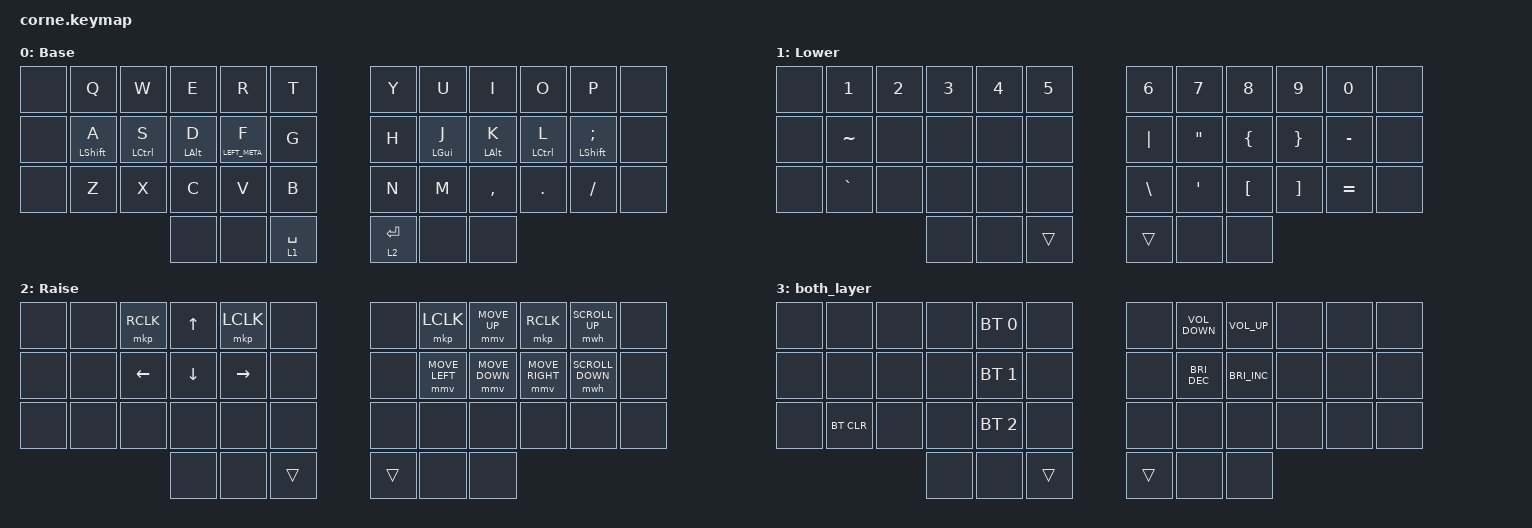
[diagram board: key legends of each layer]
/*
 * Copyright (c) 2020 The ZMK Contributors
 *
 * SPDX-License-Identifier: MIT
 * MOUSE SUPPORT: https://gist.github.com/krissen/dd27082e7ab0575619c7a31f4d2ec7ae
 * KEYMAP EDITOR: https://github.com/nickcoutsos/keymap-editor
 * MOUSE WHEEL REFERENCE: https://git.kemonine.info/kemonine/keyboard/commit/45d8c3530a40c2923cae3f1c22f27f6ed89b84cc

 * MOUSE CODES
 * &mkp RCLK   
 * &mkp LCLK
 * 
 * &mwh SCROLL_UP 		
 * &mwh SCROLL_DOWN 		
 * 
 * &mmv MOVE_UP  
 * &mmv MOVE_LEFT  
 * &mmv MOVE_DOWN  
 * &mmv MOVE_RIGHT

 */

#include <behaviors.dtsi>
#include <dt-bindings/zmk/bt.h>
#include <dt-bindings/zmk/keys.h>
#include <dt-bindings/zmk/mouse.h>

#define U_MOUSE_MOVE_MAX 1100                     /* <--- New max speed setting (default: 600) */

#undef MOVE_UP
#undef MOVE_DOWN
#undef MOVE_LEFT
#undef MOVE_RIGHT

#define MOVE_UP MOVE_VERT(-U_MOUSE_MOVE_MAX)
#define MOVE_DOWN MOVE_VERT(U_MOUSE_MOVE_MAX)
#define MOVE_LEFT MOVE_HOR(-U_MOUSE_MOVE_MAX)
#define MOVE_RIGHT MOVE_HOR(U_MOUSE_MOVE_MAX)

&mmv {
    time-to-max-speed-ms = <50>;/* <--- How long time until max speed is reached (default: 500) */
};

#define U_MOUSE_SCROLL_MAX 50                    /* <--- New max speed setting (default: 10) */

#undef SCROLL_UP
#undef SCROLL_DOWN
#undef SCROLL_LEFT
#undef SCROLL_RIGHT

#define SCROLL_UP SCROLL_VERT(U_MOUSE_SCROLL_MAX)
#define SCROLL_DOWN SCROLL_VERT(-U_MOUSE_SCROLL_MAX)
#define SCROLL_LEFT SCROLL_HOR(-U_MOUSE_SCROLL_MAX)
#define SCROLL_RIGHT SCROLL_HOR(U_MOUSE_SCROLL_MAX)

&mwh {
    time-to-max-speed-ms = <50>;/* <--- How long time until max speed is reached */
};

/ {
    combos {
        compatible = "zmk,combos";

        tab {
            bindings = <&kp TAB>;
            key-positions = <13 14>;
        };

        esc {
            bindings = <&kp ESC>;
            key-positions = <2 1>;
        };

        backspace {
            bindings = <&kp BACKSPACE>;
            key-positions = <9 10>;
        };

        keyT {
            bindings = <&kp T>;
            key-positions = <4 3>;
        };

        KeyG {
            bindings = <&kp G>;
            key-positions = <16 15>;
        };

        KeyB {
            bindings = <&kp B>;
            key-positions = <27 28>;
        };

        KeyY {
            bindings = <&kp Y>;
            key-positions = <7 8>;
        };

        KeyH {
            bindings = <&kp H>;
            key-positions = <19 20>;
        };

        KeyN {
            bindings = <&kp N>;
            key-positions = <31 32>;
        };
    };

    behaviors {
        hold_tap: hold_tap {
            compatible = "zmk,behavior-hold-tap";
            label = "HOLD_TAP";
            bindings = <&kp>, <&kp>;

            #binding-cells = <2>;
            hold-trigger-key-positions = <0 12 24 25 13 1 2 3 4 5 13 14 15 16 17 25 26 27 28 29 6 7 8 9 10 11 18 19 20 21 22 23 30 31 32 33 34 35 36 37 38 39 40 41>;
            tapping-term-ms = <200>;
        };

        hml: hml {
            compatible = "zmk,behavior-hold-tap";
            label = "HML";
            bindings = <&kp>, <&kp>;

            #binding-cells = <2>;
            hold-trigger-key-positions = <6 7 8 9 10 11 18 19 20 21 22 23 30 31 32 33 34 35 39 40 41>;
            tapping-term-ms = <200>;
        };

        hmr: hmr {
            compatible = "zmk,behavior-hold-tap";
            label = "HMR";
            bindings = <&kp>, <&kp>;

            #binding-cells = <2>;
            tapping-term-ms = <200>;
            hold-trigger-key-positions = <0 1 2 3 4 5 12 13 14 15 16 17 24 25 26 27 28 29 36 37 38>;
        };

        hold_tap_layer: hold_tap_layer {
            compatible = "zmk,behavior-hold-tap";
            label = "HOLD_TAP_LAYER";
            bindings = <&mo>, <&kp>;

            #binding-cells = <2>;
            tapping-term-ms = <200>;
            hold-trigger-key-positions = <0 1 2 4 5 6 7 9 10 11 12 13 14 15 16 17 18 19 20 21 22 23 24 25 26 27 28 29 30 31 32 33 34 35 36 37 38 39 40 41 3 8>;
        };
    };

    keymap {
        compatible = "zmk,keymap";

        default_layer {
            label = "Base";
            bindings = <
&none  &kp Q              &kp W                &kp E            &kp R             &kp T                      &kp Y                    &kp U            &kp I            &kp O                &kp P                 &none
&none  &hml LEFT_SHIFT A  &hml LEFT_CONTROL S  &hml LEFT_ALT D  &hml LEFT_META F  &kp G                      &kp H                    &hmr LEFT_GUI J  &hmr LEFT_ALT K  &hmr LEFT_CONTROL L  &hmr LEFT_SHIFT SEMI  &none
&none  &kp Z              &kp X                &kp C            &kp V             &kp B                      &kp N                    &kp M            &kp COMMA        &kp DOT              &kp FSLH              &none
                                               &none            &none             &hold_tap_layer 1 SPACE    &hold_tap_layer 2 ENTER  &none            &none
            >;
        };

        lower_layer {
            label = "Lower";
            bindings = <
&none  &kp NUMBER_1  &kp NUMBER_2  &kp NUMBER_3  &kp NUMBER_4  &kp N5    &kp NUMBER_6   &kp N7             &kp N8            &kp N9             &kp NUMBER_0  &none
&none  &kp TILDE     &none         &none         &none         &none     &kp PIPE       &kp DOUBLE_QUOTES  &kp LEFT_BRACE    &kp RIGHT_BRACE    &kp MINUS     &none
&none  &kp GRAVE     &none         &none         &none         &none     &kp BACKSLASH  &kp SQT            &kp LEFT_BRACKET  &kp RIGHT_BRACKET  &kp EQUAL     &none
                                   &none         &none         &trans    &trans         &none              &none
            >;
        };

        raise_layer {
            label = "Raise";
            bindings = <
&none  &none  &mkp RCLK  &kp UP_ARROW    &mkp LCLK  &none     &none   &mkp LCLK       &mmv MOVE_UP    &mkp RCLK        &mwh SCROLL_UP    &none
&none  &none  &kp LEFT   &kp DOWN_ARROW  &kp RIGHT  &none     &none   &mmv MOVE_LEFT  &mmv MOVE_DOWN  &mmv MOVE_RIGHT  &mwh SCROLL_DOWN  &none
&none  &none  &none      &none           &none      &none     &none   &none           &none           &none            &none             &none
                         &none           &none      &trans    &trans  &none           &none
            >;
        };

        both_layer {
            bindings = <
&none  &none       &none  &none  &bt BT_SEL 0  &none     &none   &kp C_VOLUME_DOWN     &kp C_VOLUME_UP       &none  &none  &none
&none  &none       &none  &none  &bt BT_SEL 1  &none     &none   &kp C_BRIGHTNESS_DEC  &kp C_BRIGHTNESS_INC  &none  &none  &none
&none  &bt BT_CLR  &none  &none  &bt BT_SEL 2  &none     &none   &none                 &none                 &none  &none  &none
                          &none  &none         &trans    &trans  &none                 &none
            >;
        };
    };

    conditional_layers {
        compatible = "zmk,conditional-layers";

        both {
            if-layers = <2 1>;
            then-layer = <3>;
        };
    };
};
